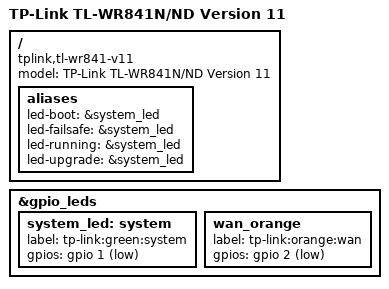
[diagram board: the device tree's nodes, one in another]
// SPDX-License-Identifier: GPL-2.0-or-later OR MIT
/dts-v1/;

#include <dt-bindings/gpio/gpio.h>
#include <dt-bindings/input/input.h>

#include "qca9533_tplink_tl-wr841.dtsi"

/ {
	compatible = "tplink,tl-wr841-v11", "qca,qca9533";
	model = "TP-Link TL-WR841N/ND Version 11";

	aliases {
		led-boot = &system_led;
		led-failsafe = &system_led;
		led-running = &system_led;
		led-upgrade = &system_led;
	};
};

&gpio_leds {
	system_led: system {
		label = "tp-link:green:system";
		gpios = <&gpio 1 GPIO_ACTIVE_LOW>;
	};

	wan_orange {
		label = "tp-link:orange:wan";
		gpios = <&gpio 2 GPIO_ACTIVE_LOW>;
	};
};
